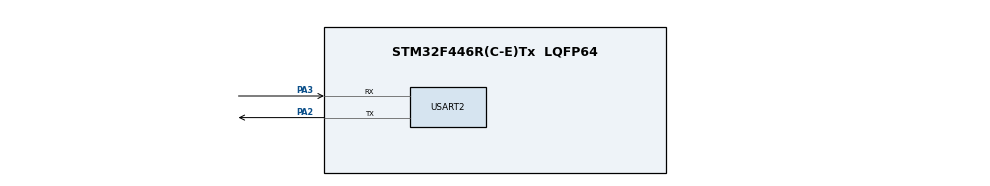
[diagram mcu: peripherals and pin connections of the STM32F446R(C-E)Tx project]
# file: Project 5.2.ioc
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Dma.Request0=USART2_TX
Dma.Request1=USART2_RX
Dma.USART2_RX.1.Direction=DMA_PERIPH_TO_MEMORY
Dma.USART2_RX.1.FIFOMode=DMA_FIFOMODE_DISABLE
Dma.USART2_RX.1.Instance=DMA1_Stream5
Dma.USART2_RX.1.MemDataAlignment=DMA_MDATAALIGN_BYTE
Dma.USART2_RX.1.MemInc=DMA_MINC_ENABLE
Dma.USART2_RX.1.Mode=DMA_CIRCULAR
Dma.USART2_RX.1.PeriphDataAlignment=DMA_PDATAALIGN_BYTE
Dma.USART2_RX.1.PeriphInc=DMA_PINC_DISABLE
Dma.USART2_RX.1.Priority=DMA_PRIORITY_LOW
Dma.USART2_TX.0.Direction=DMA_MEMORY_TO_PERIPH
Dma.USART2_TX.0.FIFOMode=DMA_FIFOMODE_DISABLE
Dma.USART2_TX.0.Instance=DMA1_Stream6
Dma.USART2_TX.0.MemDataAlignment=DMA_MDATAALIGN_BYTE
Dma.USART2_TX.0.MemInc=DMA_MINC_ENABLE
Dma.USART2_TX.0.Mode=DMA_NORMAL
Dma.USART2_TX.0.PeriphDataAlignment=DMA_PDATAALIGN_BYTE
Dma.USART2_TX.0.PeriphInc=DMA_PINC_DISABLE
Dma.USART2_TX.0.Priority=DMA_PRIORITY_LOW
Mcu.Family=STM32F4
Mcu.Name=STM32F446R(C-E)Tx
Mcu.Package=LQFP64
NVIC.DMA1_Stream5_IRQn=true\:0\:0\:false\:false\:true\:false\:true\:true
NVIC.DMA1_Stream6_IRQn=true\:0\:0\:false\:false\:true\:false\:true\:true
NVIC.PriorityGroup=NVIC_PRIORITYGROUP_4
NVIC.USART2_IRQn=true\:0\:0\:false\:false\:true\:false\:true\:true
PA2.Mode=Asynchronous
PA2.Signal=USART2_TX
PA3.Mode=Asynchronous
PA3.Signal=USART2_RX
ProjectManager.HeapSize=0x200
ProjectManager.StackSize=0x400
ProjectManager.TargetToolchain=STM32CubeIDE
RCC.CortexFreq_Value=16000000
RCC.USBFreq_Value=96000000
RCC.VCOOutputFreq_Value=192000000
USART2.VirtualMode=VM_ASYNC
board=custom

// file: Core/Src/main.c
/* USER CODE BEGIN Header */
/**
 ******************************************************************************
 * @file           : main.c
 * @brief          : Main program body
 ******************************************************************************
 * @attention
 *
 * Copyright (c) 2026 STMicroelectronics.
 * All rights reserved.
 *
 * This software is licensed under terms that can be found in the LICENSE file
 * in the root directory of this software component.
 * If no LICENSE file comes with this software, it is provided AS-IS.
 *
 ******************************************************************************
 */
/* USER CODE END Header */
#include "main.h"

#include <string.h>

/* USER CODE BEGIN PD */
# define RX_BUF_SIZE 64
/* USER CODE END PD */

UART_HandleTypeDef huart2;
DMA_HandleTypeDef hdma_usart2_tx;
DMA_HandleTypeDef hdma_usart2_rx;

/* USER CODE BEGIN PV */
uint8_t rxBuf[RX_BUF_SIZE];
volatile uint8_t txDone = 1;
/* USER CODE END PV */

void SystemClock_Config(void);
static void MX_GPIO_Init(void);
static void MX_DMA_Init(void);
static void MX_USART2_UART_Init(void);

int main(void) {

	/* MCU Configuration--------------------------------------------------------*/

	/* Reset of all peripherals, Initializes the Flash interface and the Systick. */
	HAL_Init();

	/* Configure the system clock */
	SystemClock_Config();

	/* Initialize all configured peripherals */
	MX_GPIO_Init();
	MX_DMA_Init();
	MX_USART2_UART_Init();
	/* USER CODE BEGIN 2 */
	const char *hello = "HAL DMA UART Demo -- send 64 bytes \r\n";

	/* Wait until any previous TX is done */
	while (!txDone)
		;
	txDone = 0;

	/* Start non-blocking DMA transmit */
	HAL_UART_Transmit_DMA(&huart2, (uint8_t*) hello, strlen(hello));

	/* Start background DMA receive (64 bytes per cycle) */
	HAL_UART_Receive_DMA(&huart2, rxBuf, RX_BUF_SIZE);

	/* Main loop: CPU is free, DMA handles data movement */
	while (1) {
		HAL_PWR_EnterSLEEPMode(PWR_MAINREGULATOR_ON, PWR_SLEEPENTRY_WFI);
	}
	/* USER CODE END 2 */
}

void SystemClock_Config(void) {
	RCC_OscInitTypeDef RCC_OscInitStruct = { 0 };
	RCC_ClkInitTypeDef RCC_ClkInitStruct = { 0 };

	/** Configure the main internal regulator output voltage
	 */
	__HAL_RCC_PWR_CLK_ENABLE();
	__HAL_PWR_VOLTAGESCALING_CONFIG(PWR_REGULATOR_VOLTAGE_SCALE3);

	/** Initializes the RCC Oscillators according to the specified parameters
	 * in the RCC_OscInitTypeDef structure.
	 */
	RCC_OscInitStruct.OscillatorType = RCC_OSCILLATORTYPE_HSI;
	RCC_OscInitStruct.HSIState = RCC_HSI_ON;
	RCC_OscInitStruct.HSICalibrationValue = RCC_HSICALIBRATION_DEFAULT;
	RCC_OscInitStruct.PLL.PLLState = RCC_PLL_NONE;
	if (HAL_RCC_OscConfig(&RCC_OscInitStruct) != HAL_OK) {
		Error_Handler();
	}

	/** Initializes the CPU, AHB and APB buses clocks
	 */
	RCC_ClkInitStruct.ClockType = RCC_CLOCKTYPE_HCLK | RCC_CLOCKTYPE_SYSCLK
			| RCC_CLOCKTYPE_PCLK1 | RCC_CLOCKTYPE_PCLK2;
	RCC_ClkInitStruct.SYSCLKSource = RCC_SYSCLKSOURCE_HSI;
	RCC_ClkInitStruct.AHBCLKDivider = RCC_SYSCLK_DIV1;
	RCC_ClkInitStruct.APB1CLKDivider = RCC_HCLK_DIV1;
	RCC_ClkInitStruct.APB2CLKDivider = RCC_HCLK_DIV1;

	if (HAL_RCC_ClockConfig(&RCC_ClkInitStruct, FLASH_LATENCY_0) != HAL_OK) {
		Error_Handler();
	}
}

static void MX_USART2_UART_Init(void) {

	huart2.Instance = USART2;
	huart2.Init.BaudRate = 115200;
	huart2.Init.WordLength = UART_WORDLENGTH_8B;
	huart2.Init.StopBits = UART_STOPBITS_1;
	huart2.Init.Parity = UART_PARITY_NONE;
	huart2.Init.Mode = UART_MODE_TX_RX;
	huart2.Init.HwFlowCtl = UART_HWCONTROL_NONE;
	huart2.Init.OverSampling = UART_OVERSAMPLING_16;
	if (HAL_UART_Init(&huart2) != HAL_OK) {
		Error_Handler();
	}

}

static void MX_DMA_Init(void) {

	/* DMA controller clock enable */
	__HAL_RCC_DMA1_CLK_ENABLE();

	/* DMA interrupt init */
	/* DMA1_Stream5_IRQn interrupt configuration */
	HAL_NVIC_SetPriority(DMA1_Stream5_IRQn, 0, 0);
	HAL_NVIC_EnableIRQ(DMA1_Stream5_IRQn);
	/* DMA1_Stream6_IRQn interrupt configuration */
	HAL_NVIC_SetPriority(DMA1_Stream6_IRQn, 0, 0);
	HAL_NVIC_EnableIRQ(DMA1_Stream6_IRQn);

}

static void MX_GPIO_Init(void) {

	/* GPIO Ports Clock Enable */
	__HAL_RCC_GPIOA_CLK_ENABLE();

}

/* USER CODE BEGIN 4 */
/* Called when DMA TX transfer finishes */
void HAL_UART_TxCpltCallback(UART_HandleTypeDef *huart) {
	if (huart->Instance == USART2) {
		txDone = 1;  // Signal that TX is complete
	}
}

/* Called when DMA RX fills the full buffer */
void HAL_UART_RxCpltCallback(UART_HandleTypeDef *huart) {
	if (huart->Instance == USART2) {
		// Echo back the received data using DMA
		HAL_UART_Transmit_DMA(&huart2, rxBuf, RX_BUF_SIZE);

		// Re-arm the RX DMA for the next buffer
		HAL_UART_Receive_DMA(&huart2, rxBuf, RX_BUF_SIZE);
	}
}
/* USER CODE END 4 */

void Error_Handler(void) {
	__disable_irq();
	while (1) {
	}
}
